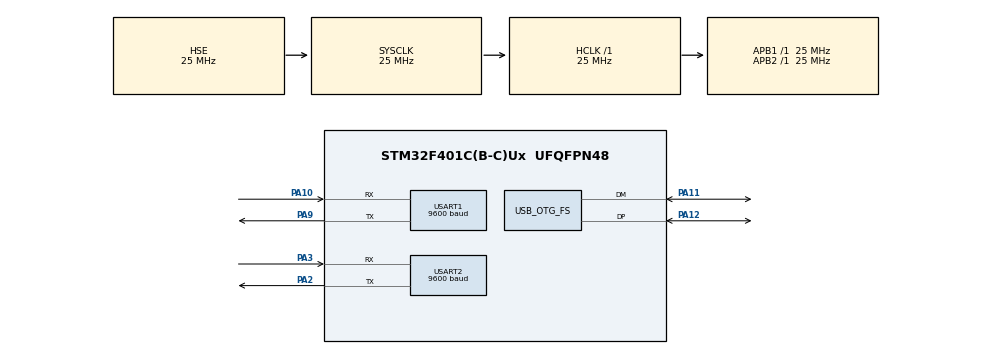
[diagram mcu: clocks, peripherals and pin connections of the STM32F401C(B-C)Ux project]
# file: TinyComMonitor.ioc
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Mcu.Family=STM32F4
Mcu.Name=STM32F401C(B-C)Ux
Mcu.Package=UFQFPN48
NVIC.OTG_FS_IRQn=true\:0\:0\:false\:false\:true\:false\:true\:true
NVIC.PriorityGroup=NVIC_PRIORITYGROUP_4
NVIC.RCC_IRQn=true\:0\:0\:false\:false\:true\:true\:false\:true
NVIC.USART1_IRQn=true\:0\:0\:false\:false\:true\:true\:true\:true
NVIC.USART2_IRQn=true\:0\:0\:false\:false\:true\:true\:true\:true
PA10.GPIO_PuPd=GPIO_PULLUP
PA10.Mode=Asynchronous
PA10.Signal=USART1_RX
PA11.Mode=Device_Only
PA11.Signal=USB_OTG_FS_DM
PA12.Mode=Device_Only
PA12.Signal=USB_OTG_FS_DP
PA2.Mode=Asynchronous
PA2.Signal=USART2_TX
PA3.GPIO_PuPd=GPIO_PULLUP
PA3.Mode=Asynchronous
PA3.Signal=USART2_RX
PA9.Mode=Asynchronous
PA9.Signal=USART1_TX
PC14-OSC32_IN.Mode=LSE-External-Oscillator
PC14-OSC32_IN.Signal=RCC_OSC32_IN
PC15-OSC32_OUT.Mode=LSE-External-Oscillator
PC15-OSC32_OUT.Signal=RCC_OSC32_OUT
PH0\ -\ OSC_IN.Mode=HSE-External-Oscillator
PH0\ -\ OSC_IN.Signal=RCC_OSC_IN
PH1\ -\ OSC_OUT.Mode=HSE-External-Oscillator
PH1\ -\ OSC_OUT.Signal=RCC_OSC_OUT
ProjectManager.HeapSize=0x200
ProjectManager.StackSize=0x400
ProjectManager.TargetToolchain=STM32CubeIDE
RCC.48MHZClocksFreq_Value=48000000
RCC.AHBFreq_Value=25000000
RCC.APB1Freq_Value=25000000
RCC.APB1TimFreq_Value=25000000
RCC.APB2Freq_Value=25000000
RCC.APB2TimFreq_Value=25000000
RCC.CortexFreq_Value=25000000
RCC.HCLKFreq_Value=25000000
RCC.HSE_VALUE=25000000
RCC.HSI_VALUE=16000000
RCC.PLLM=15
RCC.PLLN=144
RCC.PLLQ=5
RCC.SYSCLKFreq_VALUE=25000000
RCC.SYSCLKSource=RCC_SYSCLKSOURCE_HSE
RCC.VCOOutputFreq_Value=240000000
USART1.BaudRate=9600
USART1.Mode=MODE_RX
USART1.OverSampling=UART_OVERSAMPLING_16
USART1.Parity=PARITY_NONE
USART1.StopBits=STOPBITS_1
USART1.VirtualMode=VM_ASYNC
USART1.WordLength=WORDLENGTH_8B
USART2.BaudRate=9600
USART2.Mode=MODE_RX
USART2.OverSampling=UART_OVERSAMPLING_16
USART2.Parity=PARITY_NONE
USART2.StopBits=STOPBITS_1
USART2.VirtualMode=VM_ASYNC
USART2.WordLength=WORDLENGTH_8B
USB_DEVICE.CLASS_NAME_FS=CDC
USB_DEVICE.VirtualMode=Cdc
USB_DEVICE.VirtualModeFS=Cdc_FS
USB_OTG_FS.VirtualMode=Device_Only
VP_USB_DEVICE_VS_USB_DEVICE_CDC_FS.Mode=CDC_FS
board=custom

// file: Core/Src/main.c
/* USER CODE BEGIN Header */
/**
  ******************************************************************************
  * @file           : main.c
  * @brief          : Main program body
  ******************************************************************************
  * @attention
  *
  * Copyright (c) 2023 STMicroelectronics.
  * All rights reserved.
  *
  * This software is licensed under terms that can be found in the LICENSE file
  * in the root directory of this software component.
  * If no LICENSE file comes with this software, it is provided AS-IS.
  *
  ******************************************************************************
  */
/* USER CODE END Header */
#include "main.h"
#include "usb_device.h"

/* USER CODE BEGIN Includes */
#include "TinyComMonitor.h"
/* USER CODE END Includes */

void SystemClock_Config(void);
static void MX_GPIO_Init(void);

int main(void)
{

  /* MCU Configuration--------------------------------------------------------*/

  /* Reset of all peripherals, Initializes the Flash interface and the Systick. */
  HAL_Init();

  /* Configure the system clock */
  SystemClock_Config();

  /* Initialize all configured peripherals */
  MX_GPIO_Init();
  MX_USART1_UART_Init();
  MX_USART2_UART_Init();
  MX_USB_DEVICE_Init();

  /* Infinite loop */
  /* USER CODE BEGIN WHILE */
  while (1)
  {
    TinyComMonitor();
    /* USER CODE END WHILE */

  }
}

void SystemClock_Config(void)
{
  RCC_OscInitTypeDef RCC_OscInitStruct = {0};
  RCC_ClkInitTypeDef RCC_ClkInitStruct = {0};

  /** Configure the main internal regulator output voltage
  */
  __HAL_RCC_PWR_CLK_ENABLE();
  __HAL_PWR_VOLTAGESCALING_CONFIG(PWR_REGULATOR_VOLTAGE_SCALE2);

  /** Initializes the RCC Oscillators according to the specified parameters
  * in the RCC_OscInitTypeDef structure.
  */
  RCC_OscInitStruct.OscillatorType = RCC_OSCILLATORTYPE_HSE;
  RCC_OscInitStruct.HSEState = RCC_HSE_ON;
  RCC_OscInitStruct.PLL.PLLState = RCC_PLL_ON;
  RCC_OscInitStruct.PLL.PLLSource = RCC_PLLSOURCE_HSE;
  RCC_OscInitStruct.PLL.PLLM = 15;
  RCC_OscInitStruct.PLL.PLLN = 144;
  RCC_OscInitStruct.PLL.PLLP = RCC_PLLP_DIV2;
  RCC_OscInitStruct.PLL.PLLQ = 5;
  if (HAL_RCC_OscConfig(&RCC_OscInitStruct) != HAL_OK)
  {
    Error_Handler();
  }

  /** Initializes the CPU, AHB and APB buses clocks
  */
  RCC_ClkInitStruct.ClockType = RCC_CLOCKTYPE_HCLK|RCC_CLOCKTYPE_SYSCLK
                              |RCC_CLOCKTYPE_PCLK1|RCC_CLOCKTYPE_PCLK2;
  RCC_ClkInitStruct.SYSCLKSource = RCC_SYSCLKSOURCE_HSE;
  RCC_ClkInitStruct.AHBCLKDivider = RCC_SYSCLK_DIV1;
  RCC_ClkInitStruct.APB1CLKDivider = RCC_HCLK_DIV1;
  RCC_ClkInitStruct.APB2CLKDivider = RCC_HCLK_DIV1;

  if (HAL_RCC_ClockConfig(&RCC_ClkInitStruct, FLASH_LATENCY_0) != HAL_OK)
  {
    Error_Handler();
  }
}

void MX_USART1_UART_Init(void)
{

  LL_USART_InitTypeDef USART_InitStruct = {0};

  LL_GPIO_InitTypeDef GPIO_InitStruct = {0};

  /* Peripheral clock enable */
  LL_APB2_GRP1_EnableClock(LL_APB2_GRP1_PERIPH_USART1);

  LL_AHB1_GRP1_EnableClock(LL_AHB1_GRP1_PERIPH_GPIOA);
  /**USART1 GPIO Configuration
  PA9   ------> USART1_TX
  PA10   ------> USART1_RX
  */
  GPIO_InitStruct.Pin = LL_GPIO_PIN_9;
  GPIO_InitStruct.Mode = LL_GPIO_MODE_ALTERNATE;
  GPIO_InitStruct.Speed = LL_GPIO_SPEED_FREQ_VERY_HIGH;
  GPIO_InitStruct.OutputType = LL_GPIO_OUTPUT_PUSHPULL;
  GPIO_InitStruct.Pull = LL_GPIO_PULL_NO;
  GPIO_InitStruct.Alternate = LL_GPIO_AF_7;
  LL_GPIO_Init(GPIOA, &GPIO_InitStruct);

  GPIO_InitStruct.Pin = LL_GPIO_PIN_10;
  GPIO_InitStruct.Mode = LL_GPIO_MODE_ALTERNATE;
  GPIO_InitStruct.Speed = LL_GPIO_SPEED_FREQ_VERY_HIGH;
  GPIO_InitStruct.OutputType = LL_GPIO_OUTPUT_PUSHPULL;
  GPIO_InitStruct.Pull = LL_GPIO_PULL_UP;
  GPIO_InitStruct.Alternate = LL_GPIO_AF_7;
  LL_GPIO_Init(GPIOA, &GPIO_InitStruct);

  /* USART1 interrupt Init */
  NVIC_SetPriority(USART1_IRQn, NVIC_EncodePriority(NVIC_GetPriorityGrouping(),0, 0));
  NVIC_EnableIRQ(USART1_IRQn);

  USART_InitStruct.BaudRate = 9600;
  USART_InitStruct.DataWidth = LL_USART_DATAWIDTH_8B;
  USART_InitStruct.StopBits = LL_USART_STOPBITS_1;
  USART_InitStruct.Parity = LL_USART_PARITY_NONE;
  USART_InitStruct.TransferDirection = LL_USART_DIRECTION_RX;
  USART_InitStruct.HardwareFlowControl = LL_USART_HWCONTROL_NONE;
  USART_InitStruct.OverSampling = LL_USART_OVERSAMPLING_16;
  LL_USART_Init(USART1, &USART_InitStruct);
  LL_USART_ConfigAsyncMode(USART1);
  LL_USART_Enable(USART1);

}

void MX_USART2_UART_Init(void)
{

  LL_USART_InitTypeDef USART_InitStruct = {0};

  LL_GPIO_InitTypeDef GPIO_InitStruct = {0};

  /* Peripheral clock enable */
  LL_APB1_GRP1_EnableClock(LL_APB1_GRP1_PERIPH_USART2);

  LL_AHB1_GRP1_EnableClock(LL_AHB1_GRP1_PERIPH_GPIOA);
  /**USART2 GPIO Configuration
  PA2   ------> USART2_TX
  PA3   ------> USART2_RX
  */
  GPIO_InitStruct.Pin = LL_GPIO_PIN_2;
  GPIO_InitStruct.Mode = LL_GPIO_MODE_ALTERNATE;
  GPIO_InitStruct.Speed = LL_GPIO_SPEED_FREQ_VERY_HIGH;
  GPIO_InitStruct.OutputType = LL_GPIO_OUTPUT_PUSHPULL;
  GPIO_InitStruct.Pull = LL_GPIO_PULL_NO;
  GPIO_InitStruct.Alternate = LL_GPIO_AF_7;
  LL_GPIO_Init(GPIOA, &GPIO_InitStruct);

  GPIO_InitStruct.Pin = LL_GPIO_PIN_3;
  GPIO_InitStruct.Mode = LL_GPIO_MODE_ALTERNATE;
  GPIO_InitStruct.Speed = LL_GPIO_SPEED_FREQ_VERY_HIGH;
  GPIO_InitStruct.OutputType = LL_GPIO_OUTPUT_PUSHPULL;
  GPIO_InitStruct.Pull = LL_GPIO_PULL_UP;
  GPIO_InitStruct.Alternate = LL_GPIO_AF_7;
  LL_GPIO_Init(GPIOA, &GPIO_InitStruct);

  /* USART2 interrupt Init */
  NVIC_SetPriority(USART2_IRQn, NVIC_EncodePriority(NVIC_GetPriorityGrouping(),0, 0));
  NVIC_EnableIRQ(USART2_IRQn);

  USART_InitStruct.BaudRate = 9600;
  USART_InitStruct.DataWidth = LL_USART_DATAWIDTH_8B;
  USART_InitStruct.StopBits = LL_USART_STOPBITS_1;
  USART_InitStruct.Parity = LL_USART_PARITY_NONE;
  USART_InitStruct.TransferDirection = LL_USART_DIRECTION_RX;
  USART_InitStruct.HardwareFlowControl = LL_USART_HWCONTROL_NONE;
  USART_InitStruct.OverSampling = LL_USART_OVERSAMPLING_16;
  LL_USART_Init(USART2, &USART_InitStruct);
  LL_USART_ConfigAsyncMode(USART2);
  LL_USART_Enable(USART2);

}

static void MX_GPIO_Init(void)
{

  /* GPIO Ports Clock Enable */
  __HAL_RCC_GPIOC_CLK_ENABLE();
  __HAL_RCC_GPIOH_CLK_ENABLE();
  __HAL_RCC_GPIOA_CLK_ENABLE();

}

void Error_Handler(void)
{
  __disable_irq();
  while (1)
  {
  }
}
